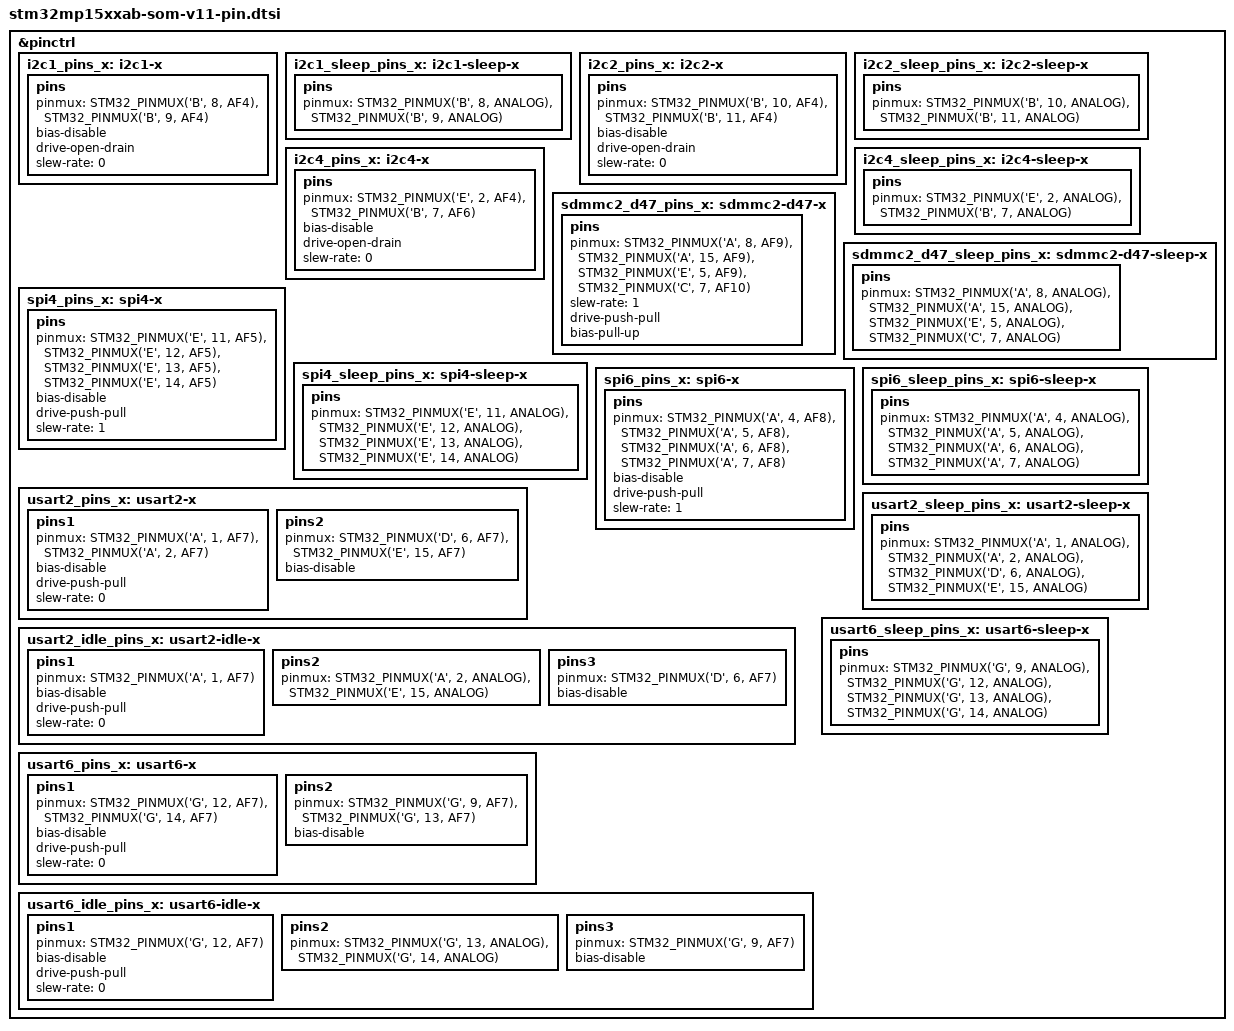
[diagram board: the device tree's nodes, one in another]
// SPDX-License-Identifier: (GPL-2.0+ OR BSD-3-Clause)
/*
 * Copyright (C) OneKiwi 2022 - All Rights Reserved
 * Author: Thanh Duong <thanh.duong.vs@gmail.com> for OneKiwi.
 */
#include <dt-bindings/pinctrl/stm32-pinfunc.h>

&pinctrl {
	i2c1_pins_x: i2c1-x {
		pins {
			pinmux = <STM32_PINMUX('B', 8, AF4)>, /* I2C1_SCL */
					 <STM32_PINMUX('B', 9, AF4)>; /* I2C1_SDA */
			bias-disable;
			drive-open-drain;
			slew-rate = <0>;
		};
	};

	i2c1_sleep_pins_x: i2c1-sleep-x {
		pins {
			pinmux = <STM32_PINMUX('B', 8, ANALOG)>, /* I2C1_SCL */
					 <STM32_PINMUX('B', 9, ANALOG)>; /* I2C1_SDA */
		};
	};

	i2c2_pins_x: i2c2-x {
		pins {
			pinmux = <STM32_PINMUX('B', 10, AF4)>, /* I2C2_SCL */
					 <STM32_PINMUX('B', 11, AF4)>; /* I2C2_SDA */
			bias-disable;
			drive-open-drain;
			slew-rate = <0>;
		};
	};

	i2c2_sleep_pins_x: i2c2-sleep-x {
		pins {
			pinmux = <STM32_PINMUX('B', 10, ANALOG)>, /* I2C2_SCL */
					 <STM32_PINMUX('B', 11, ANALOG)>; /* I2C2_SDA */
		};
	};

	i2c4_pins_x: i2c4-x {
		pins {
			pinmux = <STM32_PINMUX('E', 2, AF4)>, /* I2C4_SCL */
				 <STM32_PINMUX('B', 7, AF6)>; /* I2C4_SDA */
			bias-disable;
			drive-open-drain;
			slew-rate = <0>;
		};
	};

	i2c4_sleep_pins_x: i2c4-sleep-x {
		pins {
			pinmux = <STM32_PINMUX('E', 2, ANALOG)>, /* I2C4_SCL */
				 <STM32_PINMUX('B', 7, ANALOG)>; /* I2C4_SDA */
		};
	};

	sdmmc2_d47_pins_x: sdmmc2-d47-x {
		pins {
			pinmux = <STM32_PINMUX('A', 8, AF9)>, /* SDMMC2_D4 */
				 <STM32_PINMUX('A', 15, AF9)>, /* SDMMC2_D5 */
				 <STM32_PINMUX('E', 5, AF9)>, /* SDMMC2_D6 */
				 <STM32_PINMUX('C', 7, AF10)>; /* SDMMC2_D7 */
			slew-rate = <1>;
			drive-push-pull;
			bias-pull-up;
		};
	};

	sdmmc2_d47_sleep_pins_x: sdmmc2-d47-sleep-x {
		pins {
			pinmux = <STM32_PINMUX('A', 8, ANALOG)>, /* SDMMC2_D4 */
				 <STM32_PINMUX('A', 15, ANALOG)>, /* SDMMC2_D5 */
				 <STM32_PINMUX('E', 5, ANALOG)>, /* SDMMC2_D6 */
				 <STM32_PINMUX('C', 7, ANALOG)>; /* SDMMC2_D7 */
		};
	};

	spi4_pins_x: spi4-x {
		pins {
			pinmux = <STM32_PINMUX('E', 11, AF5)>, /* SPI4_NSS */
					 <STM32_PINMUX('E', 12, AF5)>, /* SPI4_SCK */
					 <STM32_PINMUX('E', 13, AF5)>, /* SPI4_MISO */
					 <STM32_PINMUX('E', 14, AF5)>; /* SPI4_MOSI */
			bias-disable;
			drive-push-pull;
			slew-rate = <1>;
		};
	};

	spi4_sleep_pins_x: spi4-sleep-x {
		pins {
			pinmux = <STM32_PINMUX('E', 11, ANALOG)>, /* SPI4_NSS */
					 <STM32_PINMUX('E', 12, ANALOG)>, /* SPI4_SCK */
					 <STM32_PINMUX('E', 13, ANALOG)>, /* SPI4_MISO */
					 <STM32_PINMUX('E', 14, ANALOG)>; /* SPI4_MOSI */
		};
	};

	spi6_pins_x: spi6-x {
		pins {
			pinmux = <STM32_PINMUX('A', 4, AF8)>, /* SPI6_NSS */
					 <STM32_PINMUX('A', 5, AF8)>, /* SPI6_SCK */
					 <STM32_PINMUX('A', 6, AF8)>, /* SPI6_MISO */
					 <STM32_PINMUX('A', 7, AF8)>; /* SPI6_MOSI */
			bias-disable;
			drive-push-pull;
			slew-rate = <1>;
		};
	};

	spi6_sleep_pins_x: spi6-sleep-x {
		pins {
			pinmux = <STM32_PINMUX('A', 4, ANALOG)>, /* SPI6_NSS */
					 <STM32_PINMUX('A', 5, ANALOG)>, /* SPI6_SCK */
					 <STM32_PINMUX('A', 6, ANALOG)>, /* SPI6_MISO */
					 <STM32_PINMUX('A', 7, ANALOG)>; /* SPI6_MOSI */
		};
	};

	usart2_pins_x: usart2-x {
		pins1 {
			pinmux = <STM32_PINMUX('A', 1, AF7)>, /* USART2_RTS */
					 <STM32_PINMUX('A', 2, AF7)>; /* USART2_TX */
			bias-disable;
			drive-push-pull;
			slew-rate = <0>;
		};
		pins2 {
			pinmux = <STM32_PINMUX('D', 6, AF7)>, /* USART2_RX */
					 <STM32_PINMUX('E', 15, AF7)>; /* USART2_CTS */
			bias-disable;
		};
	};

	usart2_idle_pins_x: usart2-idle-x {
		pins1 {
			pinmux = <STM32_PINMUX('A', 1, AF7)>; /* USART2_RTS */
			bias-disable;
			drive-push-pull;
			slew-rate = <0>;
		};
		pins2 {
			pinmux = <STM32_PINMUX('A', 2, ANALOG)>, /* USART2_TX */
					 <STM32_PINMUX('E', 15, ANALOG)>; /* USART2_CTS */
		};
		pins3 {
			pinmux = <STM32_PINMUX('D', 6, AF7)>; /* USART2_RX */
			bias-disable;
		};
	};

	usart2_sleep_pins_x: usart2-sleep-x {
		pins {
			pinmux = <STM32_PINMUX('A', 1, ANALOG)>, /* USART2_RTS */
					 <STM32_PINMUX('A', 2, ANALOG)>, /* USART2_TX */
					 <STM32_PINMUX('D', 6, ANALOG)>, /* USART2_RX */
					 <STM32_PINMUX('E', 15, ANALOG)>; /* USART2_CTS */
		};
	};

	usart6_pins_x: usart6-x {
		pins1 {
			pinmux = <STM32_PINMUX('G', 12, AF7)>, /* USART6_RTS */
					 <STM32_PINMUX('G', 14, AF7)>; /* USART6_TX */
			bias-disable;
			drive-push-pull;
			slew-rate = <0>;
		};
		pins2 {
			pinmux = <STM32_PINMUX('G', 9, AF7)>, /* USART6_RX */
					 <STM32_PINMUX('G', 13, AF7)>; /* USART6_CTS */
			bias-disable;
		};
	};

	usart6_idle_pins_x: usart6-idle-x {
		pins1 {
			pinmux = <STM32_PINMUX('G', 12, AF7)>; /* USART6_RTS */
			bias-disable;
			drive-push-pull;
			slew-rate = <0>;
		};
		pins2 {
			pinmux = <STM32_PINMUX('G', 13, ANALOG)>, /* USART6_CTS */
					 <STM32_PINMUX('G', 14, ANALOG)>; /* USART6_TX */
		};
		pins3 {
			pinmux = <STM32_PINMUX('G', 9, AF7)>; /* USART6_RX */
			bias-disable;
		};
	};

	usart6_sleep_pins_x: usart6-sleep-x {
		pins {
			pinmux = <STM32_PINMUX('G', 9, ANALOG)>, /* USART6_RX */
					 <STM32_PINMUX('G', 12, ANALOG)>, /* USART6_RTS */
					 <STM32_PINMUX('G', 13, ANALOG)>, /* USART6_CTS */
					 <STM32_PINMUX('G', 14, ANALOG)>; /* USART6_TX */
		};
	};
};
